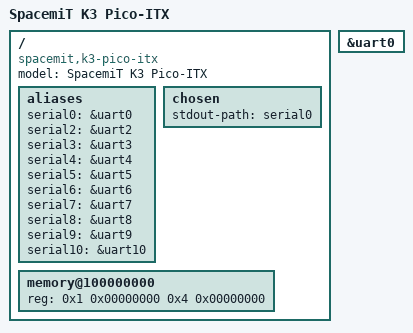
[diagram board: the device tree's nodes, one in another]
// SPDX-License-Identifier: (GPL-2.0 OR MIT)
/*
 * Copyright (c) 2025 SpacemiT (Hangzhou) Technology Co. Ltd
 * Copyright (c) 2025 Guodong Xu <guodong@riscstar.com>
 */

#include "k3.dtsi"

/ {
	model = "SpacemiT K3 Pico-ITX";
	compatible = "spacemit,k3-pico-itx", "spacemit,k3";

	aliases {
		serial0 = &uart0;
		serial2 = &uart2;
		serial3 = &uart3;
		serial4 = &uart4;
		serial5 = &uart5;
		serial6 = &uart6;
		serial7 = &uart7;
		serial8 = &uart8;
		serial9 = &uart9;
		serial10 = &uart10;
	};

	chosen {
		stdout-path = "serial0";
	};

	memory@100000000 {
		device_type = "memory";
		reg = <0x1 0x00000000 0x4 0x00000000>;
	};
};

&uart0 {
	status = "okay";
};
